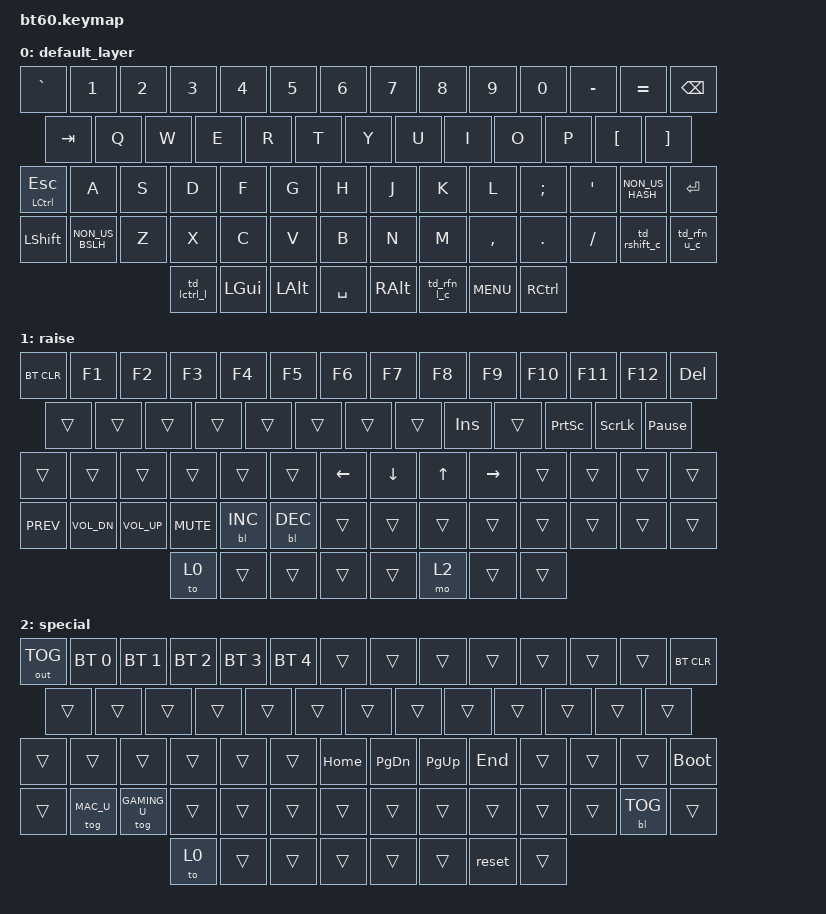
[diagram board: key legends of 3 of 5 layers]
#include <behaviors.dtsi>
#include <dt-bindings/zmk/keys.h>
#include <dt-bindings/zmk/bt.h>
#include <dt-bindings/zmk/rgb.h>
#include <dt-bindings/zmk/backlight.h>
#include <dt-bindings/zmk/outputs.h>

#define ___ &trans

#define DEFAULT 0
#define RAISE   1
#define SPECIAL 2
#define MAC_U   3
#define GAMING_U 4

#define MO_TOG(layer) &mo_tog layer layer   // Macro to apply momentary-layer-on-hold/toggle-layer-on-tap to a specific layer

#define COMBO(name, POS, LAYERS, BINDINGS) \
    / { \
        combos { \
            compatible = "zmk,combos"; \
            name { \
                timeout-ms = <50>; \
                key-positions = <POS>; \
                layers = <LAYERS>; \
                bindings = <BINDINGS>; \
            }; \
        }; \
    };

/* ZMK_UNICODE */
#define UC_LEAD_MACWIN  &macro_press &kp LALT      // macOS/Windows-Alt-Codes
#define UC_LEAD_LINUX   &macro_tap &kp LS(LC(U))   // Linux
#define UC_LEAD_WINDOWS &macro_tap &kp RALT &kp U  // Windows + WinCompose (default)

#define UC_TRAIL_MACWIN  &macro_release &kp LALT  // macOS/Windows-Alt-Codes
#define UC_TRAIL_LINUX   &macro_tap &kp SPACE     // Linux
#define UC_TRAIL_WINDOWS &macro_tap &kp RET       // Windows + WinCompose (default)

#define ZMK_HELPER_STRINGIFY(x) #x
#define UC_MACRO_LINUX(name, unicode_bindings) \
    / { \
        macros { \
            name: name { \
                compatible = "zmk,behavior-macro"; \
                label = ZMK_HELPER_STRINGIFY(UC_MACRO_ ## name); \
                wait-ms = <0>; \
                tap-ms = <0>; \
                #binding-cells = <0>; \
                bindings = <UC_LEAD_LINUX>, <&macro_tap unicode_bindings>, <UC_TRAIL_LINUX>; \
            }; \
        }; \
    };
#define UC_MACRO_MACWIN(name, unicode_bindings) \
    / { \
        macros { \
            name: name { \
                compatible = "zmk,behavior-macro"; \
                label = ZMK_HELPER_STRINGIFY(UC_MACRO_ ## name); \
                wait-ms = <0>; \
                tap-ms = <0>; \
                #binding-cells = <0>; \
                bindings = <UC_LEAD_MACWIN>, <&macro_tap unicode_bindings>, <UC_TRAIL_MACWIN>; \
            }; \
        }; \
    };

#define UC_MODMORPH(name, uc_binding, shifted_uc_binding) \
    / { \
        behaviors { \
            name: name { \
                compatible = "zmk,behavior-mod-morph"; \
                label = ZMK_HELPER_STRINGIFY(UC_MORPH_ ## name); \
                #binding-cells = <0>; \
                bindings = <uc_binding>, <shifted_uc_binding>; \
                mods = <(MOD_LSFT|MOD_RSFT)>; \
            }; \
        }; \
    };

#define ZMK_UNICODE_SINGLE(name, L0, L1, L2, L3) \
    UC_MACRO(name ## _lower, &kp L0 &kp L1 &kp L2 &kp L3) \
    UC_MODMORPH(name, &name ## _lower, &none)

#define ZMK_UNICODE_PAIR_LINUX(name, L0, L1, L2, L3, U0, U1, U2, U3) \
    UC_MACRO_LINUX(name ## _lower, &kp L0 &kp L1 &kp L2 &kp L3) \
    UC_MACRO_LINUX(name ## _upper, &kp U0 &kp U1 &kp U2 &kp U3) \
    UC_MODMORPH(name, &name ## _lower, &name ## _upper)

#define ZMK_UNICODE_PAIR_MACWIN(name, L0, L1, L2, L3, U0, U1, U2, U3) \
    UC_MACRO_MACWIN(name ## _lower, &kp L0 &kp L1 &kp L2 &kp L3) \
    UC_MACRO_MACWIN(name ## _upper, &kp U0 &kp U1 &kp U2 &kp U3) \
    UC_MODMORPH(name, &name ## _lower, &name ## _upper)

ZMK_UNICODE_PAIR_MACWIN(mwn_no_ae,  N0, N0,  E, N6,   N0, N0,  C, N6)
ZMK_UNICODE_PAIR_MACWIN(mwn_no_ao,  N0, N0,  E, N5,   N0, N0,  C, N5)
ZMK_UNICODE_PAIR_MACWIN(mwn_no_oe,  N0, N0,  F, N8,   N0, N0,  D, N8)
ZMK_UNICODE_PAIR_LINUX(lnx_no_ae,  N0, N0,  E, N6,   N0, N0,  C, N6)
ZMK_UNICODE_PAIR_LINUX(lnx_no_ao,  N0, N0,  E, N5,   N0, N0,  C, N5)
ZMK_UNICODE_PAIR_LINUX(lnx_no_oe,  N0, N0,  F, N8,   N0, N0,  D, N8)
COMBO(lnx_oe_comb, 54 37, DEFAULT, &lnx_no_oe)
COMBO(lnx_ae_comb, 54 38, DEFAULT, &lnx_no_ae)
COMBO(lnx_ao_comb, 54 25, DEFAULT, &lnx_no_ao)
COMBO(mwn_oe_comb, 54 37, MAC_U, &mwn_no_oe)
COMBO(mwn_ae_comb, 54 38, MAC_U, &mwn_no_ae)
COMBO(mwn_ao_comb, 54 25, MAC_U, &mwn_no_ao)


/ {
    behaviors {
        mo_tog: behavior_mo_tog {
            compatible = "zmk,behavior-hold-tap";
            label = "mo_tog";
            #binding-cells = <2>;
            flavor = "hold-preferred";
            tapping-term-ms = <200>;
            bindings = <&mo>, <&tog>;
        };
        td_rfn_u_c: rfn_u {
            compatible = "zmk,behavior-tap-dance";
            label = "RFN_UPPER";
            #binding-cells = <0>;
            tapping-term-ms = <200>;
            bindings = <&mo 1>, <&tog 1>;
        };
        td_rfn_l_c: rfn_l {
            compatible = "zmk,behavior-tap-dance";
            label = "RFN_LOWER";
            #binding-cells = <0>;
            tapping-term-ms = <200>;
            bindings = <&mo 1>, <&mo 2>;
        };
        td_lctrl_l: lctrl_l {
            compatible = "zmk,behavior-tap-dance";
            label = "LCTRL_LOWER";
            #binding-cells = <0>;
            tapping-term-ms = <200>;
            bindings = <&mo 1>, <&mo 2>;
        };
        td_lshift_c: lshift_caps {
            compatible = "zmk,behavior-tap-dance";
            label = "LSHIFT_CAPS";
            #binding-cells = <0>;
            tapping-term-ms = <200>;
            bindings = <&kp LSHFT>, <&kp CAPS>;
        };
        td_rshift_c: rshift_caps {
            compatible = "zmk,behavior-tap-dance";
            label = "RSHIFT_CAPS";
            #binding-cells = <0>;
            tapping-term-ms = <200>;
            bindings = <&kp RSHFT>, <&kp CAPS>;
        };
    };

	keymap {
		compatible = "zmk,keymap";

		default_layer {
				// ------------------------------------------------------------------------------------------
				// |  `  |  1  |  2  |  3  |  4  |  5  |  6  |  7  |  8  |  9  |  0  |  -  |  =  |   BKSP
				// | TAB  |  Q  |  W  |  E  |  R  |  T  |  Y  |  U  |  I  |  O  |  P  |  [  |  ]  |        |
				// | CAPS  |  A  |  S  |  D  |  F  |  G  |  H  |  J  |  K  |  L  |  ;  |  '  |  #  | ENTER |
				// |  SHIFT|  \ |  Z  | trans  |  .  | /   |    SHIFT    |
				// |  CTL  |  WIN  |  ALT  |            SPACE               | ALT | 1    |  MENU    |  CTRL|
				// ------------------------------------------------------------------------------------------
			bindings = <

				&kp GRAVE &kp N1 &kp N2 &kp N3 &kp N4 &kp N5 &kp N6 &kp N7 &kp  N8   &kp  N9 &kp  N0  &kp MINUS &kp EQUAL &kp BSPC
				&kp TAB   &kp Q  &kp W  &kp E  &kp R  &kp T  &kp Y  &kp U  &kp  I    &kp  O  &kp  P   &kp LBKT &kp RBKT
				&mt LCTRL ESC   &kp A  &kp S  &kp D  &kp F  &kp G  &kp H  &kp J  &kp  K    &kp  L  &kp SEMI &kp SQT &kp NON_US_HASH  &kp RET
				&kp LSHIFT &kp NON_US_BSLH &kp Z  &kp X  &kp C  &kp V  &kp B  &kp N  &kp M  &kp COMMA &kp DOT &kp FSLH         &td_rshift_c &td_rfn_u_c
				&td_lctrl_l &kp LGUI &kp LALT            &kp SPACE                          &kp RALT  &td_rfn_l_c &kp C_MENU    &kp RCTRL
			>;
			sensor-bindings = <&inc_dec_kp C_VOL_UP C_VOL_DN>;
		};
		raise {
			bindings = <
				&bt BT_CLR &kp F1 &kp F2 &kp F3 &kp F4 &kp F5 &kp F6 &kp F7 &kp F8 &kp F9 &kp F10 &kp F11 &kp F12 &kp DEL
				&trans &trans &trans &trans &trans &trans &trans &trans &kp INS &trans &kp PSCRN &kp SLCK &kp PAUSE_BREAK
				&trans &trans &trans &trans &trans &trans &kp LEFT &kp DOWN &kp UP &kp RIGHT &trans &trans &trans &trans
				&kp C_PREV &kp C_VOL_DN &kp C_VOL_UP &kp C_MUTE &bl BL_INC &bl BL_DEC &trans &trans &trans &trans &trans &trans  &trans &trans
				&to 0 &trans  &trans              &trans                            &trans   &mo 2   &trans &trans
			>;
			sensor-bindings = <&inc_dec_kp C_VOL_UP C_VOL_DN>;
		};
		special {
			bindings = <
				&out OUT_TOG &bt BT_SEL 0 &bt BT_SEL 1 &bt BT_SEL 2 &bt BT_SEL 3 &bt BT_SEL 4 &trans &trans &trans &trans &trans &trans &trans &bt BT_CLR
				&trans &trans &trans &trans &trans &trans &trans &trans &trans &trans &trans &trans &trans
				&trans &trans &trans &trans &trans &trans &kp HOME &kp PG_DN &kp PG_UP &kp END &trans &trans &trans &bootloader
				&trans &tog MAC_U &tog GAMING_U &trans &trans &trans &trans &trans &trans &trans &trans &trans  &bl BL_TOG &trans
				&to 0 &trans  &trans              &trans                            &trans   &trans   &reset &trans
			>;
			sensor-bindings = <&inc_dec_kp C_VOL_UP C_VOL_DN>;
		};


		mac_unicode {
			bindings = <
				___ ___ ___ ___ ___ ___ ___ ___ ___ ___ ___ ___ ___ ___
				___ ___ ___ ___ ___ ___ ___ ___ ___ ___ ___ ___ ___
				___ ___ ___ ___ ___ ___ ___ ___ ___ ___ ___ ___ ___ ___
				___ ___ ___ ___ ___ ___ ___ ___ ___ ___ ___ ___  ___
				___ ___  ___              ___              ___   ___  ___ ___
			>;
			sensor-bindings = <&inc_dec_kp C_VOL_UP C_VOL_DN>;
		};
		gaming {
			bindings = <
				&kp ESC    ___ ___ ___ ___ ___ ___ ___ ___ ___ ___ ___ ___ ___
				___        ___ ___ ___ ___ ___ ___ ___ ___ ___ ___ ___ ___
				&kp LCTRL  ___ ___ ___ ___ ___ ___ ___ ___ ___ ___ ___ ___ ___
				&kp LSHIFT ___ ___ ___ ___ ___ ___ ___ ___ ___ ___ ___  ___
				&kp LCTRL  ___  ___              ___              ___   ___  ___ ___
			>;
			sensor-bindings = <&inc_dec_kp C_VOL_UP C_VOL_DN>;
		};

	};
};

